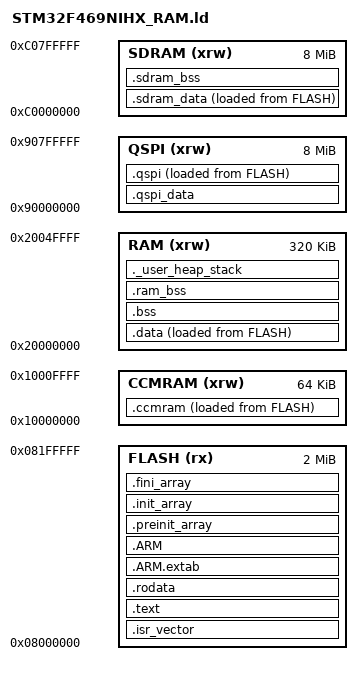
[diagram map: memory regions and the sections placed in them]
/*
******************************************************************************
**
** @file        : LinkerScript.ld
**
** @author      : Auto-generated by STM32CubeIDE
**
**  Abstract    : Linker script for STM32F469I-DISCO Board embedding STM32F469NIHx Device from stm32f4 series
**                      2048Kbytes FLASH
**                      64Kbytes CCMRAM
**                      320Kbytes RAM
**
**                Set heap size, stack size and stack location according
**                to application requirements.
**
**                Set memory bank area and size if external memory is used
**
**  Target      : STMicroelectronics STM32
**
**  Distribution: The file is distributed as is, without any warranty
**                of any kind.
**
******************************************************************************
** @attention
**
** <h2><center>&copy; Copyright (c) 2021 STMicroelectronics.
** All rights reserved.</center></h2>
**
** This software component is licensed by ST under BSD 3-Clause license,
** the "License"; You may not use this file except in compliance with the
** License. You may obtain a copy of the License at:
**                        opensource.org/licenses/BSD-3-Clause
**
******************************************************************************
*/

/* Entry Point */
ENTRY(Reset_Handler)

/* Highest address of the user mode stack */
_estack = ORIGIN(RAM) + LENGTH(RAM); /* end of "RAM" Ram type memory */
/*_estack = ORIGIN(CCMRAM) + LENGTH(CCMRAM); /* end of "RAM" Ram type memory */

_Min_Heap_Size = 0x200 ; /* required amount of heap */
_Min_Stack_Size = 0x400 ; /* required amount of stack */

/* Memories definition */
MEMORY
{
  CCMRAM	(xrw)	: ORIGIN = 0x10000000, LENGTH = 64K
  RAM		(xrw)	: ORIGIN = 0x20000000, LENGTH = 320K
  FLASH		(rx)	: ORIGIN = 0x08000000, LENGTH = 2048K
  SDRAM		(xrw)	: ORIGIN = 0xC0000000, LENGTH = 8M
  QSPI		(xrw)	: ORIGIN = 0x90000000, LENGTH = 8M
}

/* Sections */
SECTIONS
{
  /* The startup code into "FLASH" Rom type memory */
  .isr_vector :
  {
    . = ALIGN(4);
    KEEP(*(.isr_vector)) /* Startup code */
    . = ALIGN(4);
  } >FLASH

  /* The program code and other data into "FLASH" Rom type memory */
  .text :
  {
    . = ALIGN(4);
    *(.text)           /* .text sections (code) */
    *(.text*)          /* .text* sections (code) */
    *(.glue_7)         /* glue arm to thumb code */
    *(.glue_7t)        /* glue thumb to arm code */
    *(.eh_frame)

    KEEP (*(.init))
    KEEP (*(.fini))

    . = ALIGN(4);
    _etext = .;        /* define a global symbols at end of code */
  } >FLASH

  /* Constant data into "FLASH" Rom type memory */
  .rodata :
  {
    . = ALIGN(4);
    *(.rodata)         /* .rodata sections (constants, strings, etc.) */
    *(.rodata*)        /* .rodata* sections (constants, strings, etc.) */
    . = ALIGN(4);
  } >FLASH

  .ARM.extab   : {
    . = ALIGN(4);
    *(.ARM.extab* .gnu.linkonce.armextab.*)
    . = ALIGN(4);
  } >FLASH

  .ARM : {
    . = ALIGN(4);
    __exidx_start = .;
    *(.ARM.exidx*)
    __exidx_end = .;
    . = ALIGN(4);
  } >FLASH

  .qspi_data :
  {
  	*(.qspi_data .qspi_data.*)
  	*(.gnu.linkonce.r.*)
  	. = ALIGN(0x4);
  } >QSPI
  
  _qspi_init_base = LOADADDR(.qspi);
  _qspi_init_length = SIZEOF(.qspi);
  
  .qspi :
  {
    . = ALIGN(4);
    _qspi_start = .;        /* create a global symbol at qspi start */
    *(.qspi)         /* .qspi sections */
    *(.qspi*)        /* .qspi* sections */
    . = ALIGN(4);
    _qspi_end = .;         /* define a global symbols at end of qspi */
    
  } >QSPI AT> FLASH
  
  .preinit_array     :
  {
    . = ALIGN(4);
    PROVIDE_HIDDEN (__preinit_array_start = .);
    KEEP (*(.preinit_array*))
    PROVIDE_HIDDEN (__preinit_array_end = .);
    . = ALIGN(4);
  } >FLASH

  .init_array :
  {
    . = ALIGN(4);
    PROVIDE_HIDDEN (__init_array_start = .);
    KEEP (*(SORT(.init_array.*)))
    KEEP (*(.init_array*))
    PROVIDE_HIDDEN (__init_array_end = .);
    . = ALIGN(4);
  } >FLASH

  .fini_array :
  {
    . = ALIGN(4);
    PROVIDE_HIDDEN (__fini_array_start = .);
    KEEP (*(SORT(.fini_array.*)))
    KEEP (*(.fini_array*))
    PROVIDE_HIDDEN (__fini_array_end = .);
    . = ALIGN(4);
  } >FLASH

  /* Used by the startup to initialize data */
  _sidata = LOADADDR(.data);

  /* Initialized data sections into "RAM" Ram type memory */
  .data :
  {
    . = ALIGN(4);
    _sdata = .;        /* create a global symbol at data start */
    *(.data)           /* .data sections */
    *(.data*)          /* .data* sections */
    *(.RamFunc)        /* .RamFunc sections */
    *(.RamFunc*)       /* .RamFunc* sections */

    . = ALIGN(4);
    _edata = .;        /* define a global symbol at data end */

  } >RAM AT> FLASH

  /* Used by the startup to initialize data */
  _sisdram_data = LOADADDR(.sdram_data);

  /* Initialized data sections into "RAM" Ram type memory */
  .sdram_data :
  {
    . = ALIGN(4);
    _ssdram_data = .;        /* create a global symbol at data start */
    *(.sdram_data)           /* .data sections */
    *(.sdram_data*)          /* .data* sections */
    *(.sdram_RamFunc)        /* .RamFunc sections */
    *(.sdram_RamFunc*)       /* .RamFunc* sections */

    . = ALIGN(4);
    _esdram_data = .;        /* define a global symbol at data end */

  } >SDRAM AT> FLASH

  _siccmram = LOADADDR(.ccmram);

  /* CCM-RAM section
  *
  * IMPORTANT NOTE!
  * If initialized variables will be placed in this section,
  * the startup code needs to be modified to copy the init-values.
  */
  .ccmram :
  {
    . = ALIGN(4);
    _sccmram = .;       /* create a global symbol at ccmram start */
    *(.ccmram)
    *(.ccmram*)

    . = ALIGN(4);
    _eccmram = .;       /* create a global symbol at ccmram end */
  } >CCMRAM AT> FLASH

  /* Uninitialized data section into "RAM" Ram type memory */
/*  . = ALIGN(4);
  .ccmram_bss :
  {
    _sccmram_bss = .;
    __ccmram_bss_start__ = _sccmram_bss;
    *(.ccmram_bss)
    *(.ccmram_bss*)
    *(COMMON)

    . = ALIGN(4);
    _eccmram_bss = .;
    __ccmram_bss_end__ = _eccmram_bss;
  } >CCMRAM	*/

  /* Uninitialized data section into "RAM" Ram type memory */
  . = ALIGN(4);
  .bss :
  {
    /* This is used by the startup in order to initialize the .bss section */
    _sbss = .;         /* define a global symbol at bss start */
    __bss_start__ = _sbss;
    *(.bss)
    *(.bss*)
    *(COMMON)

    . = ALIGN(4);
    _ebss = .;         /* define a global symbol at bss end */
    __bss_end__ = _ebss;
  } >RAM

  /* Uninitialized sdram data section into "RAM" Ram type memory */
  . = ALIGN(4);
  .ram_bss :
  {
    _sram_bss = .;
    __ram_bss_start__ = _sram_bss;
    *(.ram_bss)
    *(.ram_bss*)

    . = ALIGN(4);
    _eram_bss = .;
    __ram_bss_end__ = _eram_bss;
  } >RAM

  /* Uninitialized sdram data section into "SDRAM" Ram type memory */
  . = ALIGN(4);
  .sdram_bss :
  {
    _ssdram_bss = .;
    __sdram_bss_start__ = _ssdram_bss;
    *(.sdram_bss)
    *(.sdram_bss*)

    . = ALIGN(4);
    _esdram_bss = .;
    __sdram_bss_end__ = _esdram_bss;
  } >SDRAM

  /* User_heap_stack section, used to check that there is enough "RAM" Ram  type memory left */
  ._user_heap_stack :
  {
    . = ALIGN(8);
    PROVIDE ( end = . );
    PROVIDE ( _end = . );
    . = . + _Min_Heap_Size;
    . = . + _Min_Stack_Size;
    . = ALIGN(8);
  } >RAM

  /* Remove information from the compiler libraries */
  /DISCARD/ :
  {
    libc.a ( * )
    libm.a ( * )
    libgcc.a ( * )
  }

  .ARM.attributes 0 : { *(.ARM.attributes) }
}
